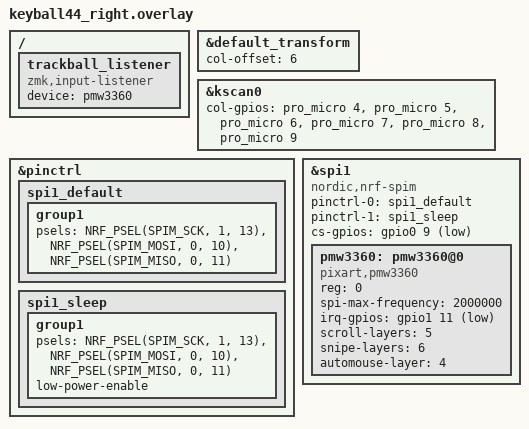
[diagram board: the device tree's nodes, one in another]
/*
 * Copyright (c) 2020 ZMK Contributors
 *
 * SPDX-License-Identifier: MIT
 */

#include "keyball44.dtsi"

/* Right side column offset */
&default_transform {
    col-offset = <6>;
};

/* Column GPIOs */
&kscan0 {
	col-gpios =
		<&pro_micro 4 GPIO_ACTIVE_HIGH>,
		<&pro_micro 5 GPIO_ACTIVE_HIGH>,
		<&pro_micro 6 GPIO_ACTIVE_HIGH>,
		<&pro_micro 7 GPIO_ACTIVE_HIGH>,
		<&pro_micro 8 GPIO_ACTIVE_HIGH>,
		<&pro_micro 9 GPIO_ACTIVE_HIGH>;
};

/* SPI pin configuration — FIXED so MOSI/MISO are different pins */
&pinctrl {
    spi1_default: spi1_default {
        group1 {
            psels = <NRF_PSEL(SPIM_SCK,  1, 13)>,   /* SCK */
                    <NRF_PSEL(SPIM_MOSI, 0, 10)>,   /* MOSI */
                    <NRF_PSEL(SPIM_MISO, 0, 11)>;   /* MISO */
        };
    };

    spi1_sleep: spi1_sleep {
        group1 {
            psels = <NRF_PSEL(SPIM_SCK,  1, 13)>,
                    <NRF_PSEL(SPIM_MOSI, 0, 10)>,
                    <NRF_PSEL(SPIM_MISO, 0, 11)>;
            low-power-enable;
        };
    };
};

/* PMW3360 on SPI1 */
&spi1 {
    status = "okay";
    compatible = "nordic,nrf-spim";

    pinctrl-0 = <&spi1_default>;
    pinctrl-1 = <&spi1_sleep>;
    pinctrl-names = "default", "sleep";

    /* Chip Select — previously recommended value */
    cs-gpios = <&gpio0 9 GPIO_ACTIVE_LOW>;

    pmw3360: pmw3360@0 {
        compatible = "pixart,pmw3360";
        reg = <0>;
        status = "okay";
        spi-max-frequency = <2000000>;

        /* IRQ/MOTION — previously recommended safe pin */
        irq-gpios = <&gpio1 11 (GPIO_ACTIVE_LOW | GPIO_PULL_UP)>;

        /* Optional behavior layers */
        scroll-layers = <5>;
        snipe-layers  = <6>;
        automouse-layer = <4>;
    };
};

/* Listener required for ZMK pointing pipeline */
 /{
  trackball_listener {
    compatible = "zmk,input-listener";
    device = <&pmw3360>;
  };
};
